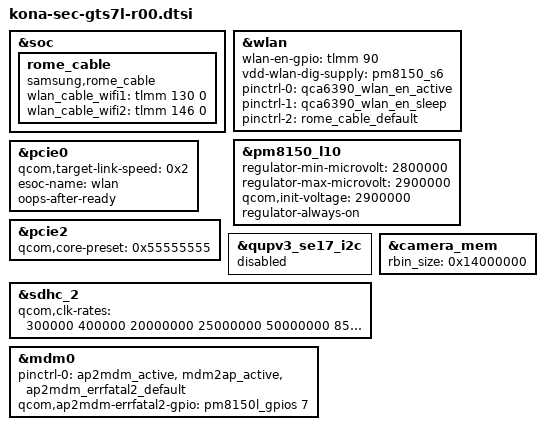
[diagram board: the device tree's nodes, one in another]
/* Copyright (c) 2019, The Linux Foundation. All rights reserved.
 *
 * This program is free software; you can redistribute it and/or modify
 * it under the terms of the GNU General Public License version 2 and
 * only version 2 as published by the Free Software Foundation.
 *
 * This program is distributed in the hope that it will be useful,
 * but WITHOUT ANY WARRANTY; without even the implied warranty of
 * MERCHANTABILITY or FITNESS FOR A PARTICULAR PURPOSE.  See the
 * GNU General Public License for more details.
 */

#include "kona-sec-gts7l-pinctrl-r00.dtsi"
#include "../drivers/audio_gts7xl_common.dtsi"
#include "kona-sec-gts7-pm-common.dtsi"
#include "../drivers/input_gts7l_common.dtsi"
#include "../drivers/displayport_gts7l_r01.dtsi"
#include "../drivers/eif_gts7l_common.dtsi"
#include "../drivers/battery-data-gts7l-common.dtsi"
#include "../drivers/bluetooth_gts7l_common.dtsi"
#include "../drivers/camera_sensor_gts7xl_r01.dtsi"
#include "../drivers/fingerprint-sensor_gts7l_r00.dtsi"
#include "../drivers/kona-sec-gts7l-display-r00.dtsi"
#include "../drivers/kona-sec-gts7l-grip-r00.dtsi"
#include "../drivers/kona-sec-gts7l-sensor-r00.dtsi"

&soc {
	rome_cable {
		compatible = "samsung,rome_cable";
		wlan_cable_wifi1 = <&tlmm 130 0>;
		wlan_cable_wifi2 = <&tlmm 146 0>;
		status = "ok";
	};
};

&wlan {
	wlan-en-gpio = <&tlmm 90 0>;
	vdd-wlan-dig-supply = <&pm8150_s6>;
	pinctrl-0 = <&qca6390_wlan_en_active>;
	pinctrl-1 = <&qca6390_wlan_en_sleep>;
	pinctrl-2 = <&rome_cable_default>;
	status = "ok";
};

&pm8150_l10 {
	regulator-min-microvolt = <2800000>;
	regulator-max-microvolt = <2900000>;
	qcom,init-voltage = <2900000>;
	regulator-always-on;
};

&pcie0 {
	qcom,target-link-speed = <0x2>; /* limit to gen2 */
	esoc-name = "wlan";
	oops-after-ready;
};

&pcie2 {
	qcom,core-preset = <0x55555555>;
};

&qupv3_se17_i2c {
	status = "disabled";
};

&camera_mem {
	rbin_size = <0x14000000>;
};

&sdhc_2 {
	qcom,clk-rates = <300000 400000 20000000 25000000
		50000000 85714285 201500000>;
}; 

&mdm0 {
	pinctrl-0 = <&ap2mdm_active &mdm2ap_active &ap2mdm_errfatal2_default>;
	qcom,ap2mdm-errfatal2-gpio = <&pm8150l_gpios 7 0>;
};
